# BL808 register map
File version: 0.1
Registers are access not given, no defined reset value unless marked. A register's access mark holds for its fields unless they carry their own. Offsets are from the block's base; [hi:lo] are bit positions.

## PDM0
Base 0x3000C000
Same registers: PDM1 0x3000D000
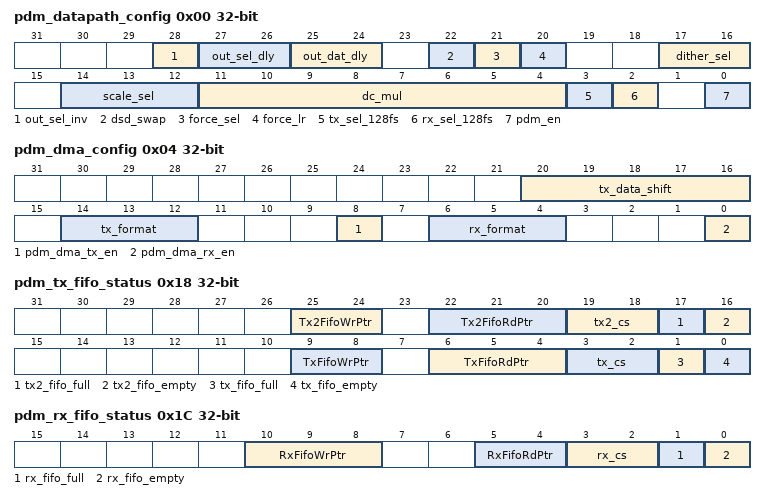
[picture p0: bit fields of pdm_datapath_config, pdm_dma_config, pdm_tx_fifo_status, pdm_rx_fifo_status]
0x00 pdm_datapath_config
  [28] out_sel_inv rw, [27:26] out_sel_dly rw, [25:24] out_dat_dly rw, [22] dsd_swap rw, [21] force_sel rw, [20] force_lr rw, [17:16] dither_sel rw, [14:12] scale_sel rw, [11:4] dc_mul rw, [3] tx_sel_128fs rw, [2] rx_sel_128fs rw, [0] pdm_en rw
0x04 pdm_dma_config
  [20:16] tx_data_shift rw, [14:12] tx_format rw, [8] pdm_dma_tx_en rw, [6:4] rx_format rw, [0] pdm_dma_rx_en rw
0x08 pdm_dma_wdata2 wo
  [31:0] pdm_dma_wdata2
0x10 pdm_dma_wdata wo
  [31:0] pdm_dma_wdata
0x14 pdm_dma_rdata ro
  [31:0] pdm_dma_rdata
0x18 pdm_tx_fifo_status
  [25:24] Tx2FifoWrPtr ro, [22:20] Tx2FifoRdPtr ro, [19:18] tx2_cs ro, [17] tx2_fifo_full ro, [16] tx2_fifo_empty ro, [9:8] TxFifoWrPtr ro, [6:4] TxFifoRdPtr ro, [3:2] tx_cs ro, [1] tx_fifo_full ro, [0] tx_fifo_empty ro
0x1C pdm_rx_fifo_status
  [10:8] RxFifoWrPtr ro, [5:4] RxFifoRdPtr ro, [3:2] rx_cs ro, [1] rx_fifo_full ro, [0] rx_fifo_empty ro

## MCU_MISC
Base 0x20009000
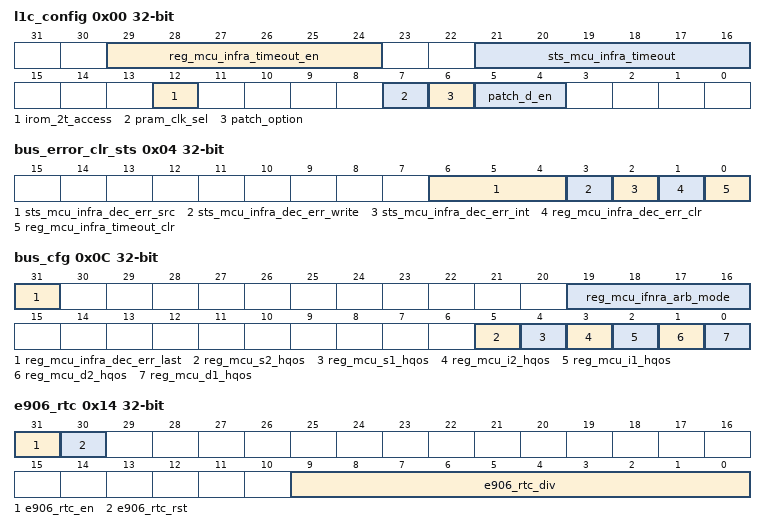
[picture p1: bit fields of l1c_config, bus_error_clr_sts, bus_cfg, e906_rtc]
0x00 l1c_config
  [29:24] reg_mcu_infra_timeout_en rw, [21:16] sts_mcu_infra_timeout ro, [12] irom_2t_access rw, [7] pram_clk_sel rw, [6] patch_option rw, [5:4] patch_d_en rw
0x04 bus_error_clr_sts
  [6:4] sts_mcu_infra_dec_err_src ro, [3] sts_mcu_infra_dec_err_write ro, [2] sts_mcu_infra_dec_err_int ro, [1] reg_mcu_infra_dec_err_clr rw, [0] reg_mcu_infra_timeout_clr rw
0x08 bus_error_addr ro
  [31:0] sts_mcu_infra_dec_err_addr
0x0C bus_cfg
  [31] reg_mcu_infra_dec_err_last rw, [19:16] reg_mcu_ifnra_arb_mode rw, [5] reg_mcu_s2_hqos rw, [4] reg_mcu_s1_hqos rw, [3] reg_mcu_i2_hqos rw, [2] reg_mcu_i1_hqos rw, [1] reg_mcu_d2_hqos rw, [0] reg_mcu_d1_hqos rw
0x10 mcu2_boot rw
  [31:0] reg_mcu2_rst_addr
0x14 e906_rtc
  [31] e906_rtc_en rw, [30] e906_rtc_rst rw, [9:0] e906_rtc_div rw
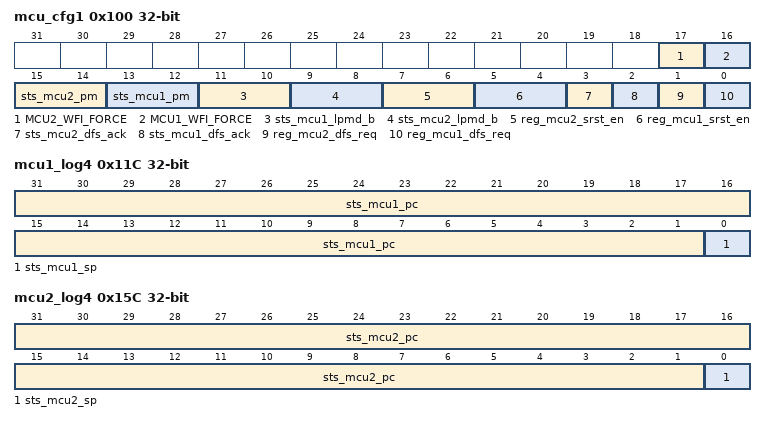
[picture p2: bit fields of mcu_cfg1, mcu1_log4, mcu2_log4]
0x100 mcu_cfg1
  [17] MCU2_WFI_FORCE rw, [16] MCU1_WFI_FORCE rw, [15:14] sts_mcu2_pm ro, [13:12] sts_mcu1_pm ro, [11:10] sts_mcu1_lpmd_b ro, [9:8] sts_mcu2_lpmd_b ro, [7:6] reg_mcu2_srst_en rw, [5:4] reg_mcu1_srst_en rw, [3] sts_mcu2_dfs_ack ro, [2] sts_mcu1_dfs_ack ro, [1] reg_mcu2_dfs_req rw, [0] reg_mcu1_dfs_req rw
0x110 mcu1_log1 ro
  [31:0] sts_mcu1_mcause
0x114 mcu1_log2 ro
  [31:0] sts_mcu1_mintstatus
0x118 mcu1_log3 ro
  [31:0] sts_mcu1_mstatus
0x11C mcu1_log4 ro
  [31:1] sts_mcu1_pc, [0] sts_mcu1_sp
0x150 mcu2_log1 ro
  [31:0] sts_mcu2_mcause
0x154 mcu2_log2 ro
  [31:0] sts_mcu2_mintstatus
0x158 mcu2_log3 ro
  [31:0] sts_mcu2_mstatus
0x15C mcu2_log4 ro
  [31:1] sts_mcu2_pc, [0] sts_mcu2_sp
0x208 irom1_misr_dataout_0 ro
  [31:0] irom1_misr_dataout_0
0x20C irom1_misr_dataout_1 ro
  [31:0] irom1_misr_dataout_1

## eFuse_Ctrl
Base 0x20056000
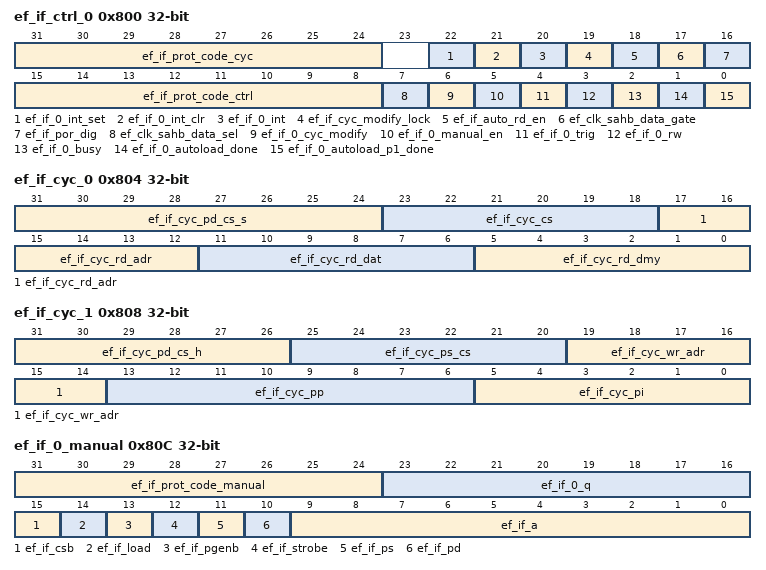
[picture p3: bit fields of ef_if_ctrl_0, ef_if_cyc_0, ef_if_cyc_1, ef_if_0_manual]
0x800 ef_if_ctrl_0
  [31:24] ef_if_prot_code_cyc rw, [22] ef_if_0_int_set rw, [21] ef_if_0_int_clr rw, [20] ef_if_0_int ro, [19] ef_if_cyc_modify_lock rw, [18] ef_if_auto_rd_en rw, [17] ef_clk_sahb_data_gate rw, [16] ef_if_por_dig rw, [15:8] ef_if_prot_code_ctrl rw, [7] ef_clk_sahb_data_sel rw, [6] ef_if_0_cyc_modify rw, [5] ef_if_0_manual_en rw, [4] ef_if_0_trig rw, [3] ef_if_0_rw rw, [2] ef_if_0_busy ro, [1] ef_if_0_autoload_done ro, [0] ef_if_0_autoload_p1_done ro
0x804 ef_if_cyc_0 rw
  [31:24] ef_if_cyc_pd_cs_s, [23:18] ef_if_cyc_cs, [17:12] ef_if_cyc_rd_adr, [11:6] ef_if_cyc_rd_dat, [5:0] ef_if_cyc_rd_dmy
0x808 ef_if_cyc_1 rw
  [31:26] ef_if_cyc_pd_cs_h, [25:20] ef_if_cyc_ps_cs, [19:14] ef_if_cyc_wr_adr, [13:6] ef_if_cyc_pp, [5:0] ef_if_cyc_pi
0x80C ef_if_0_manual access per field
  [31:24] ef_if_prot_code_manual rw, [23:16] ef_if_0_q ro, [15] ef_if_csb rw, [14] ef_if_load rw, [13] ef_if_pgenb rw, [12] ef_if_strobe rw, [11] ef_if_ps rw, [10] ef_if_pd rw, [9:0] ef_if_a rw
0x810 ef_if_0_status ro
  [31:0] ef_if_0_status
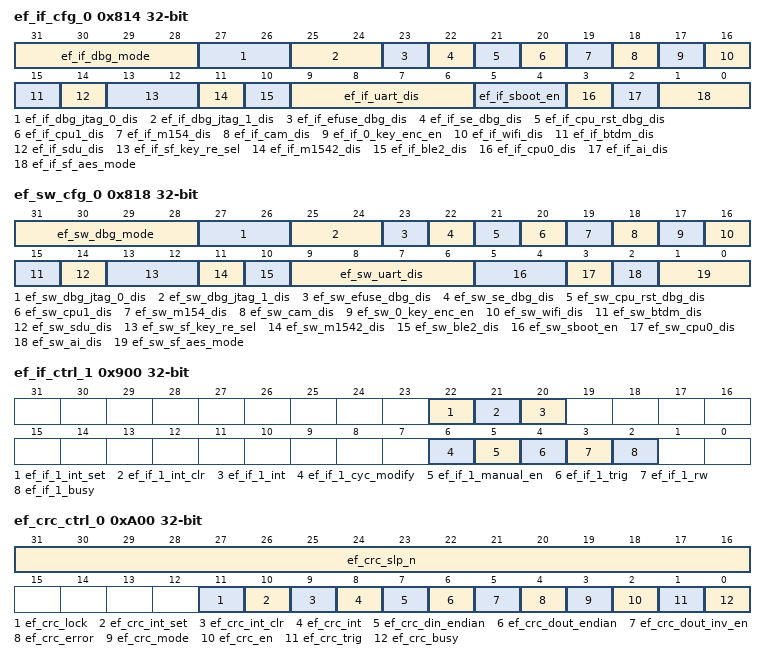
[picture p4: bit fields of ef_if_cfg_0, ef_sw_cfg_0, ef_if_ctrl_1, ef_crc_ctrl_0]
0x814 ef_if_cfg_0 ro
  [31:28] ef_if_dbg_mode, [27:26] ef_if_dbg_jtag_0_dis, [25:24] ef_if_dbg_jtag_1_dis, [23] ef_if_efuse_dbg_dis, [22] ef_if_se_dbg_dis, [21] ef_if_cpu_rst_dbg_dis, [20] ef_if_cpu1_dis, [19] ef_if_m154_dis, [18] ef_if_cam_dis, [17] ef_if_0_key_enc_en, [16] ef_if_wifi_dis, [15] ef_if_btdm_dis, [14] ef_if_sdu_dis, [13:12] ef_if_sf_key_re_sel, [11] ef_if_m1542_dis, [10] ef_if_ble2_dis, [9:6] ef_if_uart_dis, [5:4] ef_if_sboot_en, [3] ef_if_cpu0_dis, [2] ef_if_ai_dis, [1:0] ef_if_sf_aes_mode
0x818 ef_sw_cfg_0 rw
  [31:28] ef_sw_dbg_mode, [27:26] ef_sw_dbg_jtag_0_dis, [25:24] ef_sw_dbg_jtag_1_dis, [23] ef_sw_efuse_dbg_dis, [22] ef_sw_se_dbg_dis, [21] ef_sw_cpu_rst_dbg_dis, [20] ef_sw_cpu1_dis, [19] ef_sw_m154_dis, [18] ef_sw_cam_dis, [17] ef_sw_0_key_enc_en, [16] ef_sw_wifi_dis, [15] ef_sw_btdm_dis, [14] ef_sw_sdu_dis, [13:12] ef_sw_sf_key_re_sel, [11] ef_sw_m1542_dis, [10] ef_sw_ble2_dis, [9:6] ef_sw_uart_dis, [5:4] ef_sw_sboot_en, [3] ef_sw_cpu0_dis, [2] ef_sw_ai_dis, [1:0] ef_sw_sf_aes_mode
0x81C ef_reserved rw
  [31:0] ef_reserved
0x820 ef_if_ana_trim_0 ro
  [31:0] ef_if_ana_trim_0
0x824 ef_if_sw_usage_0 ro
  [31:0] ef_if_sw_usage_0
0x900 ef_if_ctrl_1
  [22] ef_if_1_int_set rw, [21] ef_if_1_int_clr rw, [20] ef_if_1_int ro, [6] ef_if_1_cyc_modify rw, [5] ef_if_1_manual_en rw, [4] ef_if_1_trig rw, [3] ef_if_1_rw rw, [2] ef_if_1_busy ro
0x904 ef_if_1_manual
  [23:16] ef_if_1_q ro
0x908 ef_if_1_status ro
  [31:0] ef_if_1_status
0x910 ef_if_ctrl_2
0x914 ef_if_2_manual
0x918 ef_if_2_status
0xA00 ef_crc_ctrl_0
  [31:16] ef_crc_slp_n rw, [11] ef_crc_lock rw, [10] ef_crc_int_set rw, [9] ef_crc_int_clr rw, [8] ef_crc_int ro, [7] ef_crc_din_endian rw, [6] ef_crc_dout_endian rw, [5] ef_crc_dout_inv_en rw, [4] ef_crc_error ro, [3] ef_crc_mode rw, [2] ef_crc_en rw, [1] ef_crc_trig rw, [0] ef_crc_busy ro
0xA04 ef_crc_ctrl_1 rw
  [31:0] ef_crc_data_0_en
0xA08 ef_crc_ctrl_2 rw
  [31:0] ef_crc_data_1_en
0xA0C ef_crc_ctrl_3 rw
  [31:0] ef_crc_iv
0xA10 ef_crc_ctrl_4 rw
  [31:0] ef_crc_golden
0xA14 ef_crc_ctrl_5 ro
  [31:0] ef_crc_dout
